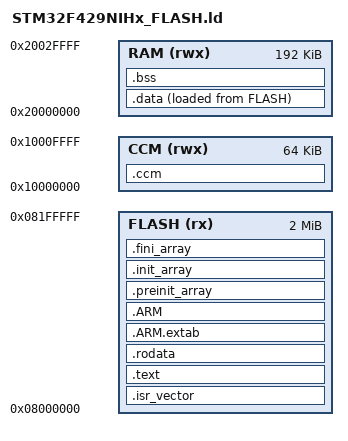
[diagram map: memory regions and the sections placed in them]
/**
 ******************************************************************************
 * @file      STM32F429NIHx_FLASH.ld
 * @brief     Linker script for STM32F429NIHx (2MB Flash, 256KB RAM)
 *            GCC toolchain
 ******************************************************************************
**/

MEMORY
{
  FLASH (rx)  : ORIGIN = 0x08000000, LENGTH = 2048K
  RAM   (rwx) : ORIGIN = 0x20000000, LENGTH =  192K
  CCM   (rwx) : ORIGIN = 0x10000000, LENGTH =   64K
}

_estack = ORIGIN(RAM) + LENGTH(RAM);

SECTIONS
{
  .isr_vector :
  {
    KEEP(*(.isr_vector))
  } > FLASH

  .text :
  {
    . = ALIGN(4);
    *(.text)
    *(.text*)
    *(.glue_7)
    *(.glue_7t)
    *(.eh_frame)
    KEEP(*(.init))
    KEEP(*(.fini))
    . = ALIGN(4);
    _etext = .;
  } > FLASH

  .rodata :
  {
    . = ALIGN(4);
    *(.rodata)
    *(.rodata*)
    . = ALIGN(4);
  } > FLASH

  .ARM.extab :
  {
    . = ALIGN(4);
    *(.ARM.extab*)
    *(.gnu.linkonce.armextab.*)
    . = ALIGN(4);
  } > FLASH

  .ARM :
  {
    . = ALIGN(4);
    __exidx_start = .;
    *(.ARM.exidx*)
    __exidx_end = .;
    . = ALIGN(4);
  } > FLASH

  .preinit_array :
  {
    . = ALIGN(4);
    __preinit_array_start = .;
    KEEP(*(.preinit_array*))
    __preinit_array_end = .;
    . = ALIGN(4);
  } > FLASH

  .init_array :
  {
    . = ALIGN(4);
    __init_array_start = .;
    KEEP(*(SORT(.init_array.*)))
    KEEP(*(.init_array*))
    __init_array_end = .;
    . = ALIGN(4);
  } > FLASH

  .fini_array :
  {
    . = ALIGN(4);
    __fini_array_start = .;
    KEEP(*(.fini_array*))
    KEEP(*(SORT(.fini_array.*)))
    __fini_array_end = .;
    . = ALIGN(4);
  } > FLASH

  _sidata = LOADADDR(.data);

  .data :
  {
    . = ALIGN(4);
    _sdata = .;
    *(.data)
    *(.data*)
    . = ALIGN(4);
    _edata = .;
  } > RAM AT> FLASH

  .bss :
  {
    . = ALIGN(4);
    _sbss = .;
    __bss_start__ = _sbss;
    *(.bss)
    *(.bss*)
    *(COMMON)
    . = ALIGN(4);
    _ebss = .;
    __bss_end__ = _ebss;
  } > RAM

  .ccm (NOLOAD) :
  {
    . = ALIGN(4);
    *(.ccm)
    *(.ccm*)
    . = ALIGN(4);
  } > CCM
}
